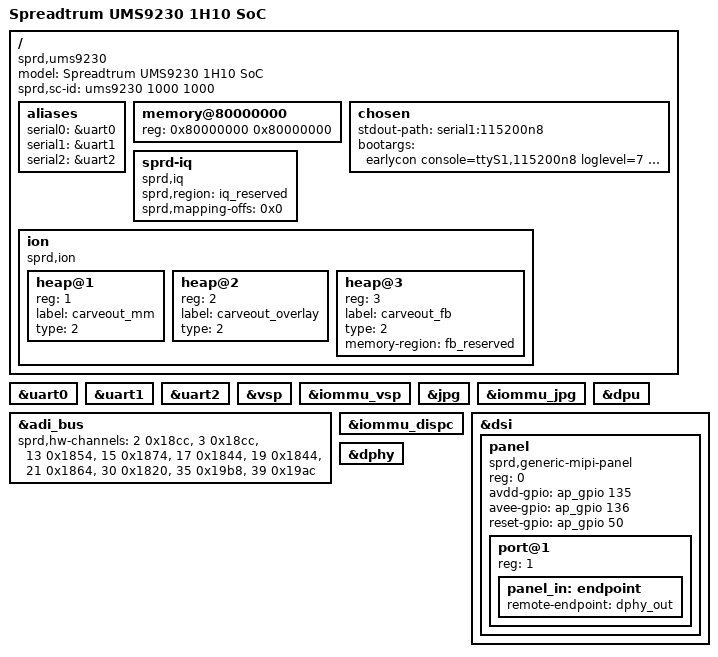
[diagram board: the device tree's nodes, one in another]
// SPDX-License-Identifier: GPL-2.0-only
/*
 * Unisoc Qogirl6 platform DTS file
 *
 * Copyright (C) 2020, Unisoc Inc.
 */

/dts-v1/;

#include <dt-bindings/gpio/gpio.h>
#include <dt-bindings/mfd/sprd,sc2730-regs.h>
#include <dt-bindings/mfd/sprd,sc2730-mask.h>
#include "ums9230.dtsi"
#include "sc2730.dtsi"
#include "sprd-sound-fe-be.dtsi"
#include "ums9230-mach.dtsi"
#include "ums9230-modem.dtsi"
#include "ums9230-wcn.dtsi"

/ {
	model = "Spreadtrum UMS9230 1H10 SoC";

	compatible = "sprd,ums9230";

	sprd,sc-id = "ums9230 1000 1000";

	aliases {
		serial0 = &uart0;
		serial1 = &uart1;
		serial2 = &uart2;
	};

	memory@80000000 {
		device_type = "memory";
		reg = <0x80000000 0x80000000>;
	};

	chosen: chosen {
		stdout-path = "serial1:115200n8";
		bootargs = "earlycon console=ttyS1,115200n8 loglevel=7 init=/init root=/dev/ram0 rw printk.devkmsg=on androidboot.selinux=permissive";
	};

	sprd-iq {
		compatible = "sprd,iq";
		sprd,region = <&iq_reserved>;
		sprd,mapping-offs = <0x0>;
	};

	ion: ion {
		compatible = "sprd,ion";
		#address-cells = <1>;
		#size-cells = <0>;

		heap@1 {
			reg = <1>;
			label = "carveout_mm";
			type = <2>;
		};

		heap@2 {
			reg = <2>;
			label = "carveout_overlay";
			type = <2>;
		};

		heap@3 {
			reg = <3>;
			label = "carveout_fb";
			type = <2>;
			memory-region = <&fb_reserved>;
		};
	};
};

&uart0 {
	status = "okay";
};

&uart1 {
	status = "okay";
};

&uart2 {
	status = "okay";
};

&vsp {
	status = "okay";
};

&iommu_vsp {
	status = "okay";
};

&jpg {
	status = "okay";
};

&iommu_jpg {
	status = "okay";
};

&adi_bus {
	sprd,hw-channels = <2 0x18cc>, <3 0x18cc>, <13 0x1854>, <15 0x1874>,
			 <17 0x1844>,<19 0x1844>, <21 0x1864>, <30 0x1820>,
			 <35 0x19b8>, <39 0x19ac>;
};

&dpu {
	status = "okay";
};

&iommu_dispc {
	status = "okay";
};

&dsi {
	status = "okay";
	#address-cells = <1>;
	#size-cells = <0>;

	panel: panel {
		compatible = "sprd,generic-mipi-panel";
		#address-cells = <1>;
		#size-cells = <0>;
		reg = <0>;

		avdd-gpio = <&ap_gpio 135 GPIO_ACTIVE_HIGH>;
		avee-gpio = <&ap_gpio 136 GPIO_ACTIVE_HIGH>;
		reset-gpio = <&ap_gpio 50 GPIO_ACTIVE_HIGH>;

		port@1 {
			reg = <1>;
			panel_in: endpoint {
				remote-endpoint = <&dphy_out>;
			};
		};
	};
};

&dphy {
	status = "okay";
};
